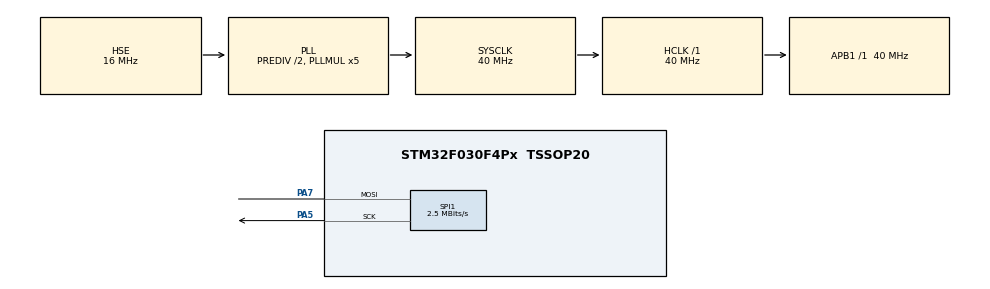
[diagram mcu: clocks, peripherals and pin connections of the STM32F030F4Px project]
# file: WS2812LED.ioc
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Mcu.Family=STM32F0
Mcu.Name=STM32F030F4Px
Mcu.Package=TSSOP20
PA5.Mode=Simplex_Bidirectional_Master
PA5.Signal=SPI1_SCK
PA7.Mode=Simplex_Bidirectional_Master
PA7.Signal=SPI1_MOSI
PF0-OSC_IN.Mode=HSE-External-Oscillator
PF0-OSC_IN.Signal=RCC_OSC_IN
PF1-OSC_OUT.Mode=HSE-External-Oscillator
PF1-OSC_OUT.Signal=RCC_OSC_OUT
ProjectManager.HeapSize=0x200
ProjectManager.StackSize=0x400
ProjectManager.TargetToolchain=STM32CubeIDE
RCC.AHBFreq_Value=40000000
RCC.APB1Freq_Value=40000000
RCC.APB1TimFreq_Value=40000000
RCC.HCLKFreq_Value=40000000
RCC.HSE_VALUE=16000000
RCC.PLLDivider=RCC_PREDIV_DIV2
RCC.PLLMUL=RCC_PLL_MUL5
RCC.PLLSourceVirtual=RCC_PLLSOURCE_HSE
RCC.SYSCLKFreq_VALUE=40000000
RCC.SYSCLKSource=RCC_SYSCLKSOURCE_PLLCLK
SPI1.BaudRatePrescaler=SPI_BAUDRATEPRESCALER_16
SPI1.CalculateBaudRate=2.5 MBits/s
SPI1.DataSize=SPI_DATASIZE_8BIT
SPI1.Direction=SPI_DIRECTION_1LINE
SPI1.Mode=SPI_MODE_MASTER
SPI1.VirtualType=VM_MASTER
board=custom

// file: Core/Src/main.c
/* USER CODE BEGIN Header */
/**
  ******************************************************************************
  * @file           : main.c
  * @brief          : Main program body
  ******************************************************************************
  * @attention
  *
  * Copyright (c) 2024 STMicroelectronics.
  * All rights reserved.
  *
  * This software is licensed under terms that can be found in the LICENSE file
  * in the root directory of this software component.
  * If no LICENSE file comes with this software, it is provided AS-IS.
  *
  ******************************************************************************
  */
/* USER CODE END Header */
#include "main.h"

/* USER CODE BEGIN Includes */
#include "WS2812_SPI.h"
/* USER CODE END Includes */

SPI_HandleTypeDef hspi1;

void SystemClock_Config(void);
static void MX_GPIO_Init(void);
static void MX_SPI1_Init(void);

/* USER CODE BEGIN 0 */

int brightness = 90; //brightness range 0 to 100

/* USER CODE END 0 */

int main(void)
{

  /* MCU Configuration--------------------------------------------------------*/

  /* Reset of all peripherals, Initializes the Flash interface and the Systick. */
  HAL_Init();

  /* Configure the system clock */
  SystemClock_Config();

  /* Initialize all configured peripherals */
  MX_GPIO_Init();
  MX_SPI1_Init();
  /* USER CODE BEGIN 2 */
  for (int i=0; i<24; i++)
  {
	  setLED(i, 0, 0, 0);
  }
  WS2812_Send();

  setLED(0, 201, 0, 255);
  setLED(23, 255, 209, 0);
  WS2812_Send();
  HAL_Delay(2000);
  /* USER CODE END 2 */

  /* Infinite loop */
  while (1)
  {

    /* USER CODE BEGIN 3 */
	  	  for (int i=0; i<24; i+=1)
	  	  {
	  		  setLED(i, 255,0,0); // Red color
	  	  }
	  	  WS2812_Send();
	  	  HAL_Delay(1000);

	  	  for (int i=0; i<24; i+=1)
	  	  {
	  		  setLED(i,0, 255, 0); // Green color
	  	  }
	  	  WS2812_Send();
	  	  HAL_Delay(1000);

	  	  for (int i=0; i<24; i+=1)
	  	  {
	  		  setLED(i,0,0,255); // Blue color
	  	  }
	  	  WS2812_Send();
	  	  HAL_Delay(1000);

  }
  /* USER CODE END 3 */
}

void SystemClock_Config(void)
{
  RCC_OscInitTypeDef RCC_OscInitStruct = {0};
  RCC_ClkInitTypeDef RCC_ClkInitStruct = {0};

  /** Initializes the RCC Oscillators according to the specified parameters
  * in the RCC_OscInitTypeDef structure.
  */
  RCC_OscInitStruct.OscillatorType = RCC_OSCILLATORTYPE_HSE;
  RCC_OscInitStruct.HSEState = RCC_HSE_ON;
  RCC_OscInitStruct.PLL.PLLState = RCC_PLL_ON;
  RCC_OscInitStruct.PLL.PLLSource = RCC_PLLSOURCE_HSE;
  RCC_OscInitStruct.PLL.PLLMUL = RCC_PLL_MUL5;
  RCC_OscInitStruct.PLL.PREDIV = RCC_PREDIV_DIV2;
  if (HAL_RCC_OscConfig(&RCC_OscInitStruct) != HAL_OK)
  {
    Error_Handler();
  }

  /** Initializes the CPU, AHB and APB buses clocks
  */
  RCC_ClkInitStruct.ClockType = RCC_CLOCKTYPE_HCLK|RCC_CLOCKTYPE_SYSCLK
                              |RCC_CLOCKTYPE_PCLK1;
  RCC_ClkInitStruct.SYSCLKSource = RCC_SYSCLKSOURCE_PLLCLK;
  RCC_ClkInitStruct.AHBCLKDivider = RCC_SYSCLK_DIV1;
  RCC_ClkInitStruct.APB1CLKDivider = RCC_HCLK_DIV1;

  if (HAL_RCC_ClockConfig(&RCC_ClkInitStruct, FLASH_LATENCY_1) != HAL_OK)
  {
    Error_Handler();
  }
}

static void MX_SPI1_Init(void)
{

  /* SPI1 parameter configuration*/
  hspi1.Instance = SPI1;
  hspi1.Init.Mode = SPI_MODE_MASTER;
  hspi1.Init.Direction = SPI_DIRECTION_1LINE;
  hspi1.Init.DataSize = SPI_DATASIZE_8BIT;
  hspi1.Init.CLKPolarity = SPI_POLARITY_LOW;
  hspi1.Init.CLKPhase = SPI_PHASE_1EDGE;
  hspi1.Init.NSS = SPI_NSS_SOFT;
  hspi1.Init.BaudRatePrescaler = SPI_BAUDRATEPRESCALER_16;
  hspi1.Init.FirstBit = SPI_FIRSTBIT_MSB;
  hspi1.Init.TIMode = SPI_TIMODE_DISABLE;
  hspi1.Init.CRCCalculation = SPI_CRCCALCULATION_DISABLE;
  hspi1.Init.CRCPolynomial = 7;
  hspi1.Init.CRCLength = SPI_CRC_LENGTH_DATASIZE;
  hspi1.Init.NSSPMode = SPI_NSS_PULSE_ENABLE;
  if (HAL_SPI_Init(&hspi1) != HAL_OK)
  {
    Error_Handler();
  }

}

static void MX_GPIO_Init(void)
{

  /* GPIO Ports Clock Enable */
  __HAL_RCC_GPIOF_CLK_ENABLE();
  __HAL_RCC_GPIOA_CLK_ENABLE();

}

void Error_Handler(void)
{
  __disable_irq();
  while (1)
  {
  }
}
